# MCU_NAVSS0_PROXY0_TARGET0_DATA_ register map
Vendor: Texas Instruments
Peripheral module from a debugger description file (folder am65x).
Registers are 32-bit, read-write, reset 0x0 unless marked. A register's access mark holds for its fields unless they carry their own. Offsets are as the file gives them; lines under a group give offsets from that group; [hi:lo] are bit positions; {n}, {i} and the like mark numbered series; 'fields as' and 'values as' point back to an identical list; <NAME> marks a mode.

## MCU_NAVSS0_PROXY0_TARGET0_DATA
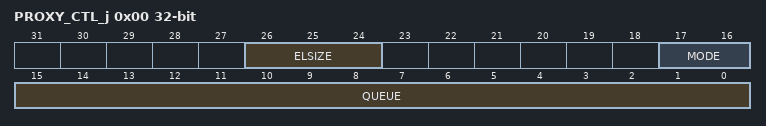
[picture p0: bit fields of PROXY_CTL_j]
0x00 PROXY_CTL_j — The Proxy Control for the proxy. NOTE: This register must be written only via 32-bit accesses. 64-bit writes are not supported and may result in data loss. Offset = 0h + (j * 1000h); where j = 0h to 3Fh
  [26:24] ELSIZE — Queue element size. This field is encoded as follows: 0 = 4 bytes 1 = 8 bytes 2 = 16 bytes 3 = 32 bytes 4 = 64 bytes 5 = 128 bytes 6 = 256 bytes 7 = 512 bytes
  [17:16] MODE — Proxy Queue Mode that determines how to access the queue. 0h = access the head of the queue 1h = access the tail of the queue 2h = peek access the head of the queue 3h = peek access the tail of the queue. NOT SUPPORTED
  [15:0] QUEUE — Proxy Queue
0x04 PROXY_STATUS_j — The Proxy Status for the proxy. NOTE: This register must be written only via 32-bit accesses. 64-bit writes are not supported and may result in data loss. Offset = 4h + (j * 1000h); where j = 0h to 3Fh
  [31] ERROR — Proxy Error status
0x200 PROXY_DATA_j_y — The Proxy Data for the proxy, target and channel Offset = 200h + (j * 1000h) + (y * 4h); where j = 0h to 3Fh, y = 0h to 7Fh
  [31:0] VAL — Proxy Data
